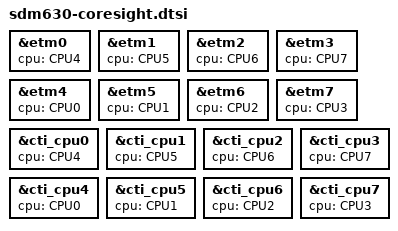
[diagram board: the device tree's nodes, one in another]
/* Copyright (c) 2016, The Linux Foundation. All rights reserved.
 *
 * This program is free software; you can redistribute it and/or modify
 * it under the terms of the GNU General Public License version 2 and
 * only version 2 as published by the Free Software Foundation.
 *
 * This program is distributed in the hope that it will be useful,
 * but WITHOUT ANY WARRANTY; without even the implied warranty of
 * MERCHANTABILITY or FITNESS FOR A PARTICULAR PURPOSE.  See the
 * GNU General Public License for more details.
 */

#include "sdm660-coresight.dtsi"

&etm0 {
	cpu = <&CPU4>;
};

&etm1 {
	cpu = <&CPU5>;
};

&etm2 {
	cpu = <&CPU6>;
};

&etm3 {
	cpu = <&CPU7>;
};

&etm4 {
	cpu = <&CPU0>;
};

&etm5 {
	cpu = <&CPU1>;
};

&etm6 {
	cpu = <&CPU2>;
};

&etm7 {
	cpu = <&CPU3>;
};

&cti_cpu0 {
	cpu = <&CPU4>;
};

&cti_cpu1 {
	cpu = <&CPU5>;
};

&cti_cpu2 {
	cpu = <&CPU6>;
};

&cti_cpu3 {
	cpu = <&CPU7>;
};

&cti_cpu4 {
	cpu = <&CPU0>;
};

&cti_cpu5 {
	cpu = <&CPU1>;
};

&cti_cpu6 {
	cpu = <&CPU2>;
};

&cti_cpu7 {
	cpu = <&CPU3>;
};

/delete-node/ &cti_turing;
